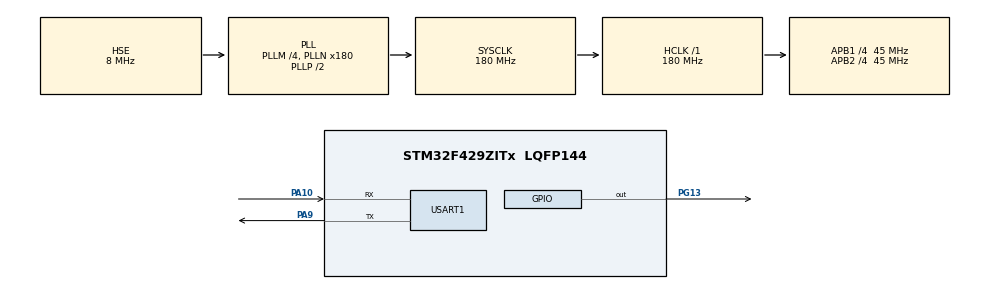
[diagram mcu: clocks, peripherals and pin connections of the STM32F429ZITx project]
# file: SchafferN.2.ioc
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Mcu.Family=STM32F4
Mcu.Name=STM32F429ZITx
Mcu.Package=LQFP144
NVIC.PriorityGroup=NVIC_PRIORITYGROUP_4
PA10.Mode=Asynchronous
PA10.Signal=USART1_RX
PA9.Mode=Asynchronous
PA9.Signal=USART1_TX
PG13.Signal=GPIO_Output
PH0/OSC_IN.Mode=HSE-External-Oscillator
PH0/OSC_IN.Signal=RCC_OSC_IN
PH1/OSC_OUT.Mode=HSE-External-Oscillator
PH1/OSC_OUT.Signal=RCC_OSC_OUT
ProjectManager.HeapSize=0x200
ProjectManager.StackSize=0x400
ProjectManager.TargetToolchain=STM32CubeIDE
RCC.48MHZClocksFreq_Value=45000000
RCC.AHBFreq_Value=180000000
RCC.APB1CLKDivider=RCC_HCLK_DIV4
RCC.APB1Freq_Value=45000000
RCC.APB1TimFreq_Value=90000000
RCC.APB2CLKDivider=RCC_HCLK_DIV4
RCC.APB2Freq_Value=45000000
RCC.APB2TimFreq_Value=90000000
RCC.CortexFreq_Value=180000000
RCC.HCLKFreq_Value=180000000
RCC.HSE_VALUE=8000000
RCC.HSI_VALUE=16000000
RCC.LSE_VALUE=32768
RCC.PLLM=4
RCC.PLLN=180
RCC.PLLQ=8
RCC.PLLSourceVirtual=RCC_PLLSOURCE_HSE
RCC.SYSCLKFreq_VALUE=180000000
RCC.SYSCLKSource=RCC_SYSCLKSOURCE_PLLCLK
RCC.VCOOutputFreq_Value=360000000
USART1.VirtualMode=VM_ASYNC
VP_RNG_VS_RNG.Mode=RNG_Activate
board=custom

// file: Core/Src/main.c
/* USER CODE BEGIN Header */
/**
  ******************************************************************************
  * @file           : main.c
  * @brief          : Main program body
  ******************************************************************************
  * @attention
  *
  * Copyright (c) 2025 STMicroelectronics.
  * All rights reserved.
  *
  * This software is licensed under terms that can be found in the LICENSE file
  * in the root directory of this software component.
  * If no LICENSE file comes with this software, it is provided AS-IS.
  *
  ******************************************************************************
  */
/* USER CODE END Header */
#include "main.h"

/* USER CODE BEGIN Includes */
#include "ga.h"
#include <stdio.h>
#include <string.h>
#include <math.h>
/* USER CODE END Includes */

RNG_HandleTypeDef hrng;

UART_HandleTypeDef huart1;

/* USER CODE BEGIN PV */
#define VOLTAGE 3.3f
#define CURRENT 0.02f
/* USER CODE END PV */

void SystemClock_Config(void);
static void MX_GPIO_Init(void);
static void MX_USART1_UART_Init(void);
static void MX_RNG_Init(void);

int main(void)
{

  /* MCU Configuration--------------------------------------------------------*/

  /* Reset of all peripherals, Initializes the Flash interface and the Systick. */
  HAL_Init();

  /* Configure the system clock */
  SystemClock_Config();

  /* Initialize all configured peripherals */
  MX_GPIO_Init();
  MX_USART1_UART_Init();
  MX_RNG_Init();
  /* USER CODE BEGIN 2 */
  char msgg[] = "UART test\r\n";
  HAL_UART_Transmit(&huart1, (uint8_t*)msgg, strlen(msgg), HAL_MAX_DELAY);

  Population pop, offspring_cross, offspring_mut, offspring_ls, combined, selected;
  Archive archive = {0};

  // Initialize population
  random_population(&pop);
  for (int i = 0; i < pop.size; i++) {
	  evaluate(&pop.solutions[i]);
  }

  CoreDebug->DEMCR |= CoreDebug_DEMCR_TRCENA_Msk;
  DWT->CYCCNT = 0;
  DWT->CTRL |= DWT_CTRL_CYCCNTENA_Msk;

  uint32_t start_cycles = DWT->CYCCNT;

  // Main loop
  for (int iter = 0; iter < MAX_ITER; iter++) {
	  // Generate offspring
	  crossover(&pop, &offspring_cross);
	  mutation(&pop, &offspring_mut);
	  local_search(&pop, &offspring_ls);

	  // Combine populations
	  combined.size = 0;
	  for (int i = 0; i < pop.size; i++) {
		  combined.solutions[combined.size++] = pop.solutions[i];
	  }
	  for (int i = 0; i < offspring_cross.size; i++) {
		  combined.solutions[combined.size++] = offspring_cross.solutions[i];
	  }
	  for (int i = 0; i < offspring_mut.size; i++) {
		  combined.solutions[combined.size++] = offspring_mut.solutions[i];
	  }
	  for (int i = 0; i < offspring_ls.size; i++) {
		  combined.solutions[combined.size++] = offspring_ls.solutions[i];
	  }

	  selection(&combined, &selected);
	  pop = selected;
	  update_archive(&pop, &archive);
  }

  uint32_t end_cycles = DWT->CYCCNT;
  uint32_t elapsed_cycles = end_cycles - start_cycles;
  float time_sec = (float)elapsed_cycles / 180000000.0f;
  float elapsed_ms = time_sec * 1000.0f;
  float energy_joules = VOLTAGE * CURRENT * time_sec;

  send_archive(&huart1, &archive);

  char msg[128];
  snprintf(msg, sizeof(msg), "Done! Time: %.2fms (%.2fs), Energy: %.4fJ\r\n", elapsed_ms, time_sec, energy_joules);
  HAL_UART_Transmit(&huart1, (uint8_t*)msg, strlen(msg), HAL_MAX_DELAY);
  /* USER CODE END 2 */

  /* Infinite loop */
  /* USER CODE BEGIN WHILE */
  while (1)
  {
	  HAL_GPIO_TogglePin(GPIOG, GPIO_PIN_13);
	  HAL_Delay(500);
    /* USER CODE END WHILE */

  }
}

void SystemClock_Config(void)
{
  RCC_OscInitTypeDef RCC_OscInitStruct = {0};
  RCC_ClkInitTypeDef RCC_ClkInitStruct = {0};

  /** Configure the main internal regulator output voltage
  */
  __HAL_RCC_PWR_CLK_ENABLE();
  __HAL_PWR_VOLTAGESCALING_CONFIG(PWR_REGULATOR_VOLTAGE_SCALE1);

  /** Initializes the RCC Oscillators according to the specified parameters
  * in the RCC_OscInitTypeDef structure.
  */
  RCC_OscInitStruct.OscillatorType = RCC_OSCILLATORTYPE_HSE;
  RCC_OscInitStruct.HSEState = RCC_HSE_ON;
  RCC_OscInitStruct.PLL.PLLState = RCC_PLL_ON;
  RCC_OscInitStruct.PLL.PLLSource = RCC_PLLSOURCE_HSE;
  RCC_OscInitStruct.PLL.PLLM = 4;
  RCC_OscInitStruct.PLL.PLLN = 180;
  RCC_OscInitStruct.PLL.PLLP = RCC_PLLP_DIV2;
  RCC_OscInitStruct.PLL.PLLQ = 8;
  if (HAL_RCC_OscConfig(&RCC_OscInitStruct) != HAL_OK)
  {
    Error_Handler();
  }

  /** Activate the Over-Drive mode
  */
  if (HAL_PWREx_EnableOverDrive() != HAL_OK)
  {
    Error_Handler();
  }

  /** Initializes the CPU, AHB and APB buses clocks
  */
  RCC_ClkInitStruct.ClockType = RCC_CLOCKTYPE_HCLK|RCC_CLOCKTYPE_SYSCLK
                              |RCC_CLOCKTYPE_PCLK1|RCC_CLOCKTYPE_PCLK2;
  RCC_ClkInitStruct.SYSCLKSource = RCC_SYSCLKSOURCE_PLLCLK;
  RCC_ClkInitStruct.AHBCLKDivider = RCC_SYSCLK_DIV1;
  RCC_ClkInitStruct.APB1CLKDivider = RCC_HCLK_DIV4;
  RCC_ClkInitStruct.APB2CLKDivider = RCC_HCLK_DIV4;

  if (HAL_RCC_ClockConfig(&RCC_ClkInitStruct, FLASH_LATENCY_5) != HAL_OK)
  {
    Error_Handler();
  }
}

static void MX_RNG_Init(void)
{

  hrng.Instance = RNG;
  if (HAL_RNG_Init(&hrng) != HAL_OK)
  {
    Error_Handler();
  }

}

static void MX_USART1_UART_Init(void)
{

  huart1.Instance = USART1;
  huart1.Init.BaudRate = 115200;
  huart1.Init.WordLength = UART_WORDLENGTH_8B;
  huart1.Init.StopBits = UART_STOPBITS_1;
  huart1.Init.Parity = UART_PARITY_NONE;
  huart1.Init.Mode = UART_MODE_TX_RX;
  huart1.Init.HwFlowCtl = UART_HWCONTROL_NONE;
  huart1.Init.OverSampling = UART_OVERSAMPLING_16;
  if (HAL_UART_Init(&huart1) != HAL_OK)
  {
    Error_Handler();
  }

}

static void MX_GPIO_Init(void)
{
  GPIO_InitTypeDef GPIO_InitStruct = {0};

  /* GPIO Ports Clock Enable */
  __HAL_RCC_GPIOH_CLK_ENABLE();
  __HAL_RCC_GPIOA_CLK_ENABLE();
  __HAL_RCC_GPIOG_CLK_ENABLE();

  /*Configure GPIO pin Output Level */
  HAL_GPIO_WritePin(GPIOG, GPIO_PIN_13, GPIO_PIN_RESET);

  /*Configure GPIO pin : PG13 */
  GPIO_InitStruct.Pin = GPIO_PIN_13;
  GPIO_InitStruct.Mode = GPIO_MODE_OUTPUT_PP;
  GPIO_InitStruct.Pull = GPIO_NOPULL;
  GPIO_InitStruct.Speed = GPIO_SPEED_FREQ_LOW;
  HAL_GPIO_Init(GPIOG, &GPIO_InitStruct);

}

void Error_Handler(void)
{
  __disable_irq();
  while (1)
  {
  }
}
